# RZT2ME register map
Vendor: Renesas Electronics Corporation; Series: RZT; File version: 1.00.00
CPU: other r0p0, little endian, MPU, no FPU, VTOR, 4 interrupt priority bits, 624 interrupts
Registers are 32-bit, read-write, reset 0x0 unless marked. A register's access mark holds for its fields unless they carry their own. Offsets are from the block's base; [hi:lo] are bit positions; 'fields as' and 'values as' point back to an identical list.

## MTU5 — Multi-Function Timer Pulse Unit Channel 5
Base 0x90001C00
0x80 TCNTU 16-bit — Timer Counter U
0x82 TGRU 16-bit reset 0xFFFF — Timer General Register U
0x84 TCRU 8-bit — Timer Control Register U
  [1:0] TPSC — Time Prescaler Select
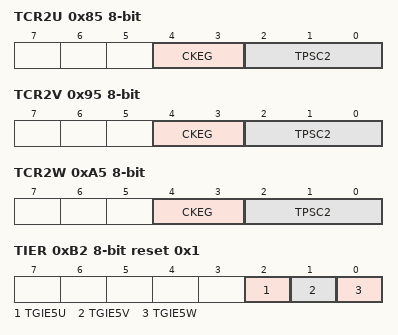
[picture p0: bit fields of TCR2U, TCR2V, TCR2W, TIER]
0x85 TCR2U 8-bit — Timer Control Register 2U
  [4:3] CKEG — Clock Edge Select
    0=Counts at the rising edge; 1=Counts at the falling edge; 0b1x=Counts at both edges
  [2:0] TPSC2 — Time Prescaler Select
0x86 TIORU 8-bit — Timer I/O Control Register U
  [4:0] IOC — I/O Control C
0x90 TCNTV 16-bit — Timer Counter V
0x92 TGRV 16-bit reset 0xFFFF — Timer General Register V
0x94 TCRV 8-bit — Timer Control Register V
  [1:0] TPSC — Time Prescaler Select
0x95 TCR2V 8-bit — Timer Control Register 2V
  fields as TCR2U
0x96 TIORV 8-bit — Timer I/O Control Register V
  [4:0] IOC — I/O Control C
0xA0 TCNTW 16-bit — Timer Counter W
0xA2 TGRW 16-bit reset 0xFFFF — Timer General Register W
0xA4 TCRW 8-bit — Timer Control Register W
  [1:0] TPSC — Time Prescaler Select
0xA5 TCR2W 8-bit — Timer Control Register 2W
  fields as TCR2U
0xA6 TIORW 8-bit — Timer I/O Control Register W
  [4:0] IOC — I/O Control C
0xB2 TIER 8-bit reset 0x1 — Timer Interrupt Enable Register
  [2] TGIE5U — TGR Interrupt Enable 5U
    0=Interrupt requests TGIU5 disabled; 1=Interrupt requests TGIU5 enabled
  [1] TGIE5V — TGR Interrupt Enable 5V
    0=Interrupt requests TGIV5 disabled; 1=Interrupt requests TGIV5 enabled
  [0] TGIE5W — TGR Interrupt Enable 5W
    0=Interrupt requests TGIW5 disabled; 1=Interrupt requests TGIW5 enabled
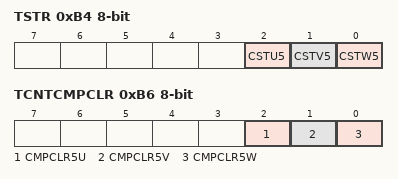
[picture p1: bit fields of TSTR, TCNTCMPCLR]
0xB4 TSTR 8-bit — Timer Start Register
  [2] CSTU5 — Counter Start U5
    0=MTU5.TCNTU counting is stopped; 1=MTU5.TCNTU performs count operation
  [1] CSTV5 — Counter Start V5
    0=MTU5.TCNTV counting is stopped; 1=MTU5.TCNTV performs count operation
  [0] CSTW5 — Counter Start W5
    0=MTU5.TCNTW counting is stopped; 1=MTU5.TCNTW performs count operation
0xB6 TCNTCMPCLR 8-bit — Timer Compare Match Clear Register
  [2] CMPCLR5U — TCNT Compare Clear 5U
    0=Disables MTU5.TCNTU to be cleared to 0x0000 at MTU5.TCNTU and MTU5.TGRU compare match or input capture; 1=Enables MTU5.TCNTU to be cleared to 0x0000 at MTU5.TCNTU and MTU5.TGRU compare match or input capture
  [1] CMPCLR5V — TCNT Compare Clear 5V
    0=Disables MTU5.TCNTV to be cleared to 0x0000 at MTU5.TCNTV and MTU5.TGRV compare match or input capture; 1=Enables MTU5.TCNTV to be cleared to 0x0000 at MTU5.TCNTV and MTU5.TGRV compare match or input capture
  [0] CMPCLR5W — TCNT Compare Clear 5W
    0=Disables MTU5.TCNTW to be cleared to 0x0000 at MTU5.TCNTW and MTU5.TGRW compare match or input capture; 1=Enables MTU5.TCNTW to be cleared to 0x0000 at MTU5.TCNTW and MTU5.TGRW compare match or input capture

## TFU — Arithmetic Unit for Trigonometric Functions
Base 0x90003000
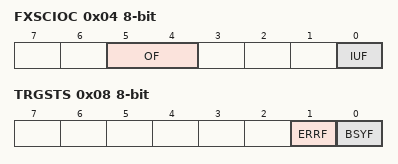
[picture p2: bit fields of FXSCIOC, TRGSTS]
0x04 FXSCIOC 8-bit — Fixed-point Sine Cosine Input/Output Setting Register
  [5:4] OF — Output format setting
    0=Q1.31; 1=Q2.30; 2=Q3.29; 3=Setting prohibited
  [0] IUF — Input unit and format setting
    0=unit, format = turn, Q1.31; 1=unit, format = radian, Q3.29
0x05 FXATIOC 8-bit — Fixed-point Arctangent hypot_k Input/Output Setting Register
  [4] OUF — Output unit and format setting
    0=unit, format = turn, Q1.31; 1=unit, format = radian, Q3.29
0x08 TRGSTS 8-bit — Trigonometric Status Register
  [1] ERRF — Input error flag
    0=No input error occurred; 1=Input error occurred
  [0] BSYF — Calculation in progress flag
    0=No calculating; 1=Calculating
0x10 FPSCDT0 — Floating-point Sine Cosine Data Register 0
0x14 FPSCDT1 — Floating-point Sine Cosine Data Register 1
0x18 FPATDT0 — Floating-point Arctangent hypot_k Data Register 0
0x1C FPATDT1 — Floating-point Arctangent hypot_k Data Register 1
0x20 FXSCDT0 — Fixed-point Sine Cosine Data Register 0
0x24 FXSCDT1 — Fixed-point Sine Cosine Data Register 1
0x28 FXATDT0 — Fixed-point Arctangent hypot_k Data Register 0
0x2C FXATDT1 — Fixed-point Arctangent hypot_k Data Register 1
0x30 DTSR0 — Data Save Restore Register 0
0x34 DTSR1 — Data Save Restore Register 1

## POEG0 — GPT Port Output Enable 0
Base 0x90006000
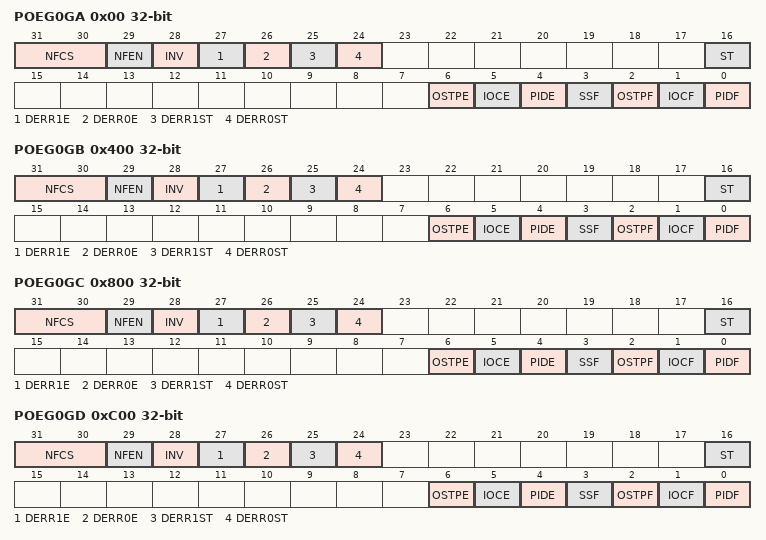
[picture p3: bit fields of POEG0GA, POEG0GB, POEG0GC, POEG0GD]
0x00 POEG0GA — POEG0 Group A Setting Register
  [31:30] NFCS — Noise filter Clock Select
    0=Samples the input level of GTETRGn pin three times per PCLKH clock; 1=Samples the input level of GTETRGn pin three times per PCLKH/8 clock; 2=Samples the input level of GTETRGn pin three times per PCLKH/32 clock; 3=Samples the input level of GTETRGn pin three times per PCLKH/128 clock
  [29] NFEN — Noise filter Enable
    0=Digital noise filter on the GTETRGn pin is disabled; 1=Digital noise filter on the GTETRGn pin is enabled
  [28] INV — GTETRGn Input Inverting
    0=Input on the GTETRGn pin is not inverted; 1=Input on the GTETRGn pin is inverted
  [27] DERR1E — Permit output disabled by DSMIF1 error detection
    0=Disable; 1=Not disabled
  [26] DERR0E — Permit output disabled by DSMIF0 error detection
    0=Disable; 1=Not disabled
  [25] DERR1ST — DSMIF1 error status
    0=Not error detect; 1=Error detect
  [24] DERR0ST — DSMIF0 error status
    0=Not error detect; 1=Error detect
  [16] ST ro — GTETRGn Input Status Flag
    0=GTETRGn input after filtering was 0; 1=GTETRGn input after filtering was 1
  [6] OSTPE — Enable Stopping Output on Stopping of Oscillation
    0=Detection of stopping of oscillation is disabled; 1=Detection of stopping of oscillation is enabled
  [5] IOCE — GPT Output Stop Request Enable
    0=Detection of stopping of output from the GPT is disabled; 1=Detection of stopping of output from the GPT is enabled
  [4] PIDE — Port Input Detection Enable
    0=Detection of input levels on the corresponding GTETRGn pin is disabled; 1=Detection of input levels on the corresponding GTETRGn pin is enabled
  [3] SSF — Software Stop Flag
    0=Software has not stopped output; 1=Software has stopped output
  [2] OSTPF — Oscillation Stop Detection Flag
    0=Stopping of oscillation was not detected; 1=Stopping of oscillation was detected
  [1] IOCF — GPT Output Stop Request Detection Flag
    0=Stopping of GPT output was not detected; 1=Stopping of GPT output was detected
  [0] PIDF — Port Input Detection Flag
    0=The selected input level was not detected on the GTETRGn pin; 1=The selected input level was detected on the GTETRGn pin
0x400 POEG0GB — POEG0 Group B Setting Register
  fields as POEG0GA
0x800 POEG0GC — POEG0 Group C Setting Register
  fields as POEG0GA
0xC00 POEG0GD — POEG0 Group D Setting Register
  fields as POEG0GA

## GSC — Global System Counter
Base 0xC0060000
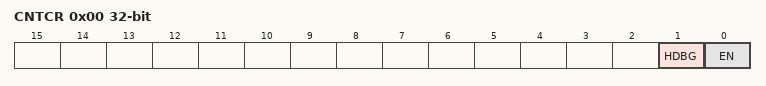
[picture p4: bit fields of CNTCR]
0x00 CNTCR — Global System Counter Control Register
  [1] HDBG — Halt on Debug
    0=Do not halt on debug, HLTDBG signal into the counter has no effect; 1=Halt on debug, when HLTDBG is driven high, the count value is held static
  [0] EN — Counter Enable
    0=The counter is disabled and not incrementing; 1=The counter is enabled and is incrementing
0x04 CNTSR ro — Global System Counter Status Register
  [1] DBGH — Debug Halted
    0=Not halt on debug; 1=Halt on debug
0x08 CNTCVL — Global System Counter Current Value Lower Register
  [31:0] CNTCVL_L_32 — Current value of the counter, lower 32 bits
0x0C CNTCVU — Global System Counter Current Value Upper Register
  [31:0] CNTCVU_U_32 — Current value of the counter, upper 32 bits
0x20 CNTFID0 — Global System Counter Base Frequency ID Register
  [31:0] FREQ — Frequency in number of ticks per second
